VERSION ""

NS_ :

BS_:

BU_:

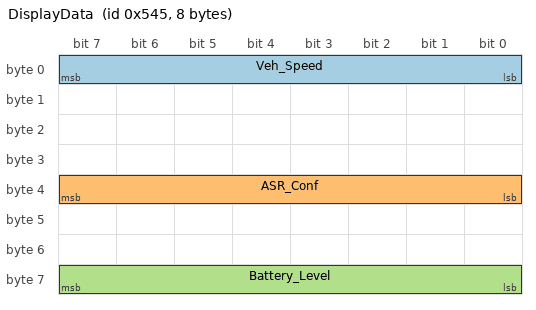
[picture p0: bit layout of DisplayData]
BO_ 1349 DisplayData: 8 Vector__XXX
 SG_ Veh_Speed : 0|8@1+ (1,0) [0|0] "" Vector__XXX
 SG_ ASR_Conf : 32|8@1+ (1,0) [0|0] "" Vector__XXX
 SG_ Battery_Level : 56|8@1+ (1,0) [0|0] "" Vector__XXX
